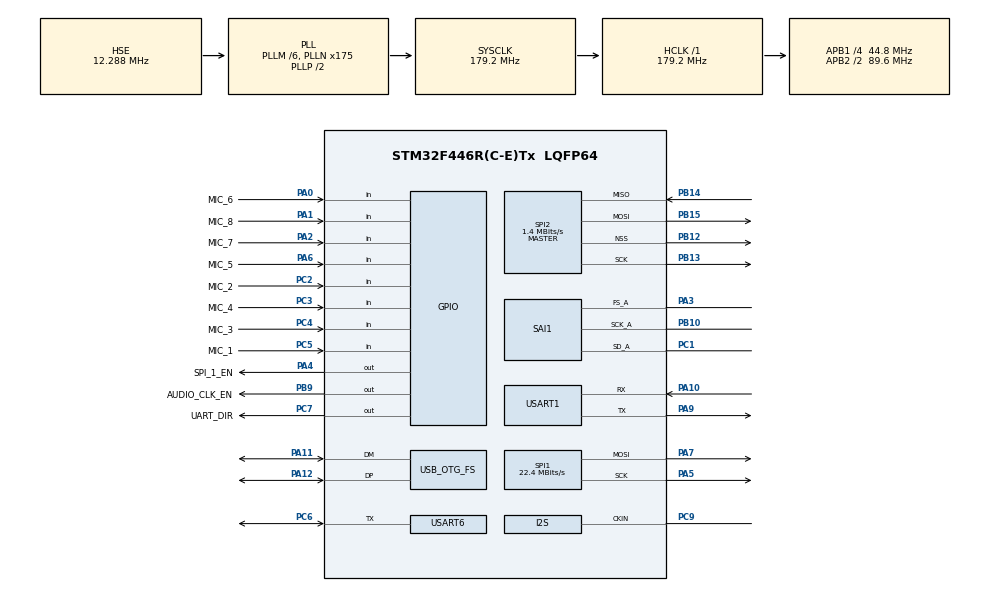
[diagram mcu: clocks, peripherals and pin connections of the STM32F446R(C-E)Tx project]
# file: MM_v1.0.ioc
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Dma.Request0=USART1_RX
Dma.Request1=USART1_TX
Dma.Request2=USART6_RX
Dma.Request3=USART6_TX
Dma.Request4=SPI2_TX
Dma.Request5=SPI1_TX
Dma.Request6=SAI1_A
Dma.SAI1_A.6.Direction=DMA_PERIPH_TO_MEMORY
Dma.SAI1_A.6.FIFOMode=DMA_FIFOMODE_DISABLE
Dma.SAI1_A.6.Instance=DMA2_Stream1
Dma.SAI1_A.6.MemDataAlignment=DMA_MDATAALIGN_WORD
Dma.SAI1_A.6.MemInc=DMA_MINC_ENABLE
Dma.SAI1_A.6.Mode=DMA_CIRCULAR
Dma.SAI1_A.6.PeriphDataAlignment=DMA_PDATAALIGN_WORD
Dma.SAI1_A.6.PeriphInc=DMA_PINC_DISABLE
Dma.SAI1_A.6.Priority=DMA_PRIORITY_HIGH
Dma.SPI1_TX.5.Direction=DMA_MEMORY_TO_PERIPH
Dma.SPI1_TX.5.FIFOMode=DMA_FIFOMODE_DISABLE
Dma.SPI1_TX.5.Instance=DMA2_Stream3
Dma.SPI1_TX.5.MemDataAlignment=DMA_MDATAALIGN_HALFWORD
Dma.SPI1_TX.5.MemInc=DMA_MINC_ENABLE
Dma.SPI1_TX.5.Mode=DMA_NORMAL
Dma.SPI1_TX.5.PeriphDataAlignment=DMA_PDATAALIGN_HALFWORD
Dma.SPI1_TX.5.PeriphInc=DMA_PINC_DISABLE
Dma.SPI1_TX.5.Priority=DMA_PRIORITY_VERY_HIGH
Dma.SPI2_TX.4.Direction=DMA_MEMORY_TO_PERIPH
Dma.SPI2_TX.4.FIFOMode=DMA_FIFOMODE_DISABLE
Dma.SPI2_TX.4.Instance=DMA1_Stream4
Dma.SPI2_TX.4.MemDataAlignment=DMA_MDATAALIGN_HALFWORD
Dma.SPI2_TX.4.MemInc=DMA_MINC_ENABLE
Dma.SPI2_TX.4.Mode=DMA_NORMAL
Dma.SPI2_TX.4.PeriphDataAlignment=DMA_PDATAALIGN_HALFWORD
Dma.SPI2_TX.4.PeriphInc=DMA_PINC_DISABLE
Dma.SPI2_TX.4.Priority=DMA_PRIORITY_LOW
Dma.USART1_RX.0.Direction=DMA_PERIPH_TO_MEMORY
Dma.USART1_RX.0.FIFOMode=DMA_FIFOMODE_DISABLE
Dma.USART1_RX.0.Instance=DMA2_Stream5
Dma.USART1_RX.0.MemDataAlignment=DMA_MDATAALIGN_BYTE
Dma.USART1_RX.0.MemInc=DMA_MINC_ENABLE
Dma.USART1_RX.0.Mode=DMA_NORMAL
Dma.USART1_RX.0.PeriphDataAlignment=DMA_PDATAALIGN_BYTE
Dma.USART1_RX.0.PeriphInc=DMA_PINC_DISABLE
Dma.USART1_RX.0.Priority=DMA_PRIORITY_LOW
Dma.USART1_TX.1.Direction=DMA_MEMORY_TO_PERIPH
Dma.USART1_TX.1.FIFOMode=DMA_FIFOMODE_DISABLE
Dma.USART1_TX.1.Instance=DMA2_Stream7
Dma.USART1_TX.1.MemDataAlignment=DMA_MDATAALIGN_BYTE
Dma.USART1_TX.1.MemInc=DMA_MINC_ENABLE
Dma.USART1_TX.1.Mode=DMA_NORMAL
Dma.USART1_TX.1.PeriphDataAlignment=DMA_PDATAALIGN_BYTE
Dma.USART1_TX.1.PeriphInc=DMA_PINC_DISABLE
Dma.USART1_TX.1.Priority=DMA_PRIORITY_LOW
Dma.USART6_RX.2.Direction=DMA_PERIPH_TO_MEMORY
Dma.USART6_RX.2.FIFOMode=DMA_FIFOMODE_DISABLE
Dma.USART6_RX.2.Instance=DMA2_Stream2
Dma.USART6_RX.2.MemDataAlignment=DMA_MDATAALIGN_BYTE
Dma.USART6_RX.2.MemInc=DMA_MINC_ENABLE
Dma.USART6_RX.2.Mode=DMA_NORMAL
Dma.USART6_RX.2.PeriphDataAlignment=DMA_PDATAALIGN_BYTE
Dma.USART6_RX.2.PeriphInc=DMA_PINC_DISABLE
Dma.USART6_RX.2.Priority=DMA_PRIORITY_LOW
Dma.USART6_TX.3.Direction=DMA_MEMORY_TO_PERIPH
Dma.USART6_TX.3.FIFOMode=DMA_FIFOMODE_DISABLE
Dma.USART6_TX.3.Instance=DMA2_Stream6
Dma.USART6_TX.3.MemDataAlignment=DMA_MDATAALIGN_BYTE
Dma.USART6_TX.3.MemInc=DMA_MINC_ENABLE
Dma.USART6_TX.3.Mode=DMA_NORMAL
Dma.USART6_TX.3.PeriphDataAlignment=DMA_PDATAALIGN_BYTE
Dma.USART6_TX.3.PeriphInc=DMA_PINC_DISABLE
Dma.USART6_TX.3.Priority=DMA_PRIORITY_LOW
Mcu.Family=STM32F4
Mcu.Name=STM32F446R(C-E)Tx
Mcu.Package=LQFP64
NVIC.DMA1_Stream4_IRQn=true\:0\:0\:false\:false\:true\:false
NVIC.DMA2_Stream1_IRQn=true\:0\:0\:false\:false\:true\:false
NVIC.DMA2_Stream2_IRQn=true\:0\:0\:false\:false\:true\:false
NVIC.DMA2_Stream3_IRQn=true\:0\:0\:false\:false\:true\:false
NVIC.DMA2_Stream5_IRQn=true\:0\:0\:false\:false\:true\:false
NVIC.DMA2_Stream6_IRQn=true\:0\:0\:false\:false\:true\:false
NVIC.DMA2_Stream7_IRQn=true\:0\:0\:false\:false\:true\:false
NVIC.OTG_FS_IRQn=true\:0\:0\:false\:false\:true\:false
NVIC.PriorityGroup=NVIC_PRIORITYGROUP_4
NVIC.SPI1_IRQn=true\:0\:0\:false\:false\:true\:true
NVIC.SPI2_IRQn=true\:0\:0\:false\:false\:true\:true
PA0-WKUP.GPIO_Label=MIC_6
PA0-WKUP.Signal=GPIO_Input
PA1.GPIO_Label=MIC_8
PA1.Signal=GPIO_Input
PA10.Mode=Asynchronous
PA10.Signal=USART1_RX
PA11.Mode=Device_Only
PA11.Signal=USB_OTG_FS_DM
PA12.Mode=Device_Only
PA12.Signal=USB_OTG_FS_DP
PA2.GPIO_Label=MIC_7
PA2.Signal=GPIO_Input
PA3.GPIO_Speed=GPIO_SPEED_FREQ_VERY_HIGH
PA3.Mode=SAI_A_Master
PA3.Signal=SAI1_FS_A
PA4.GPIO_Label=SPI_1_EN
PA4.GPIO_Speed=GPIO_SPEED_FREQ_VERY_HIGH
PA4.Signal=GPIO_Output
PA5.Mode=TX_Only_Simplex_Unidirect_Master
PA5.Signal=SPI1_SCK
PA6.GPIO_Label=MIC_5
PA6.Signal=GPIO_Input
PA7.Mode=TX_Only_Simplex_Unidirect_Master
PA7.Signal=SPI1_MOSI
PA9.Mode=Asynchronous
PA9.Signal=USART1_TX
PB10.GPIO_Speed=GPIO_SPEED_FREQ_VERY_HIGH
PB10.Mode=SAI_A_Master
PB10.Signal=SAI1_SCK_A
PB12.Mode=NSS_Signal_Hard_Output
PB12.Signal=SPI2_NSS
PB13.Mode=Full_Duplex_Master
PB13.Signal=SPI2_SCK
PB14.Mode=Full_Duplex_Master
PB14.Signal=SPI2_MISO
PB15.Mode=Full_Duplex_Master
PB15.Signal=SPI2_MOSI
PB9.GPIO_Label=AUDIO_CLK_EN
PB9.GPIO_Speed=GPIO_SPEED_FREQ_VERY_HIGH
PB9.Signal=GPIO_Output
PC1.GPIO_Speed=GPIO_SPEED_FREQ_VERY_HIGH
PC1.Mode=SAI_A_Master
PC1.Signal=SAI1_SD_A
PC14-OSC32_IN.Mode=LSE-External-Oscillator
PC14-OSC32_IN.Signal=RCC_OSC32_IN
PC15-OSC32_OUT.Mode=LSE-External-Oscillator
PC15-OSC32_OUT.Signal=RCC_OSC32_OUT
PC2.GPIO_Label=MIC_2
PC2.Signal=GPIO_Input
PC3.GPIO_Label=MIC_4
PC3.Signal=GPIO_Input
PC4.GPIO_Label=MIC_3
PC4.Signal=GPIO_Input
PC5.GPIO_Label=MIC_1
PC5.Signal=GPIO_Input
PC6.Mode=Half_duplex(single_wire_mode)
PC6.Signal=USART6_TX
PC7.GPIO_Label=UART_DIR
PC7.GPIO_Speed=GPIO_SPEED_FREQ_VERY_HIGH
PC7.Signal=GPIO_Output
PC9.GPIO_Speed=GPIO_SPEED_FREQ_VERY_HIGH
PC9.Mode=Audio_ClockIn
PC9.Signal=I2S_CKIN
PH0-OSC_IN.Mode=HSE-External-Oscillator
PH0-OSC_IN.Signal=RCC_OSC_IN
PH1-OSC_OUT.Mode=HSE-External-Oscillator
PH1-OSC_OUT.Signal=RCC_OSC_OUT
ProjectManager.HeapSize=0x2000
ProjectManager.StackSize=0x4000
ProjectManager.TargetToolchain=MDK-ARM V5
RCC.AHBFreq_Value=179200000
RCC.APB1CLKDivider=RCC_HCLK_DIV4
RCC.APB1Freq_Value=44800000
RCC.APB1TimFreq_Value=89600000
RCC.APB2CLKDivider=RCC_HCLK_DIV2
RCC.APB2Freq_Value=89600000
RCC.APB2TimFreq_Value=179200000
RCC.CortexFreq_Value=179200000
RCC.EXTERNAL_CLOCK_VALUE=12288000
RCC.HCLKFreq_Value=179200000
RCC.HSE_VALUE=12288000
RCC.PLLM=6
RCC.PLLN=175
RCC.PLLSAIM=8
RCC.PLLSAIN=125
RCC.PLLSAIP=RCC_PLLSAIP_DIV4
RCC.PLLSAIQ=4
RCC.PLLSAIQDiv=4
RCC.PLLSourceVirtual=RCC_PLLSOURCE_HSE
RCC.SAIACLockSelection=RCC_SAI1CLKSOURCE_EXT
RCC.SYSCLKFreq_VALUE=179200000
RCC.SYSCLKSource=RCC_SYSCLKSOURCE_PLLCLK
RCC.USBCLockSelection=RCC_CLK48CLKSOURCE_PLLSAIP
RCC.USBFreq_Value=48000000
RCC.VCOOutputFreq_Value=358400000
SAI1.ActiveFrameLength-SAI_A_Master=1
SAI1.AudioFrequency-SAI_A_Master=SAI_AUDIO_FREQUENCY_22K
SAI1.AudioMode-SAI_A_Master=SAI_MODEMASTER_RX
SAI1.DataSize-SAI_A_Master=SAI_DATASIZE_20
SAI1.ErrorAudioFreq-SAI_A_Master=50.0 %
SAI1.FSOffset-SAI_A_Master=SAI_FS_FIRSTBIT
SAI1.FSPolarity-SAI_A_Master=SAI_FS_ACTIVE_HIGH
SAI1.FirstBitOffset-SAI_A_Master=0
SAI1.FrameLength-SAI_A_Master=256
SAI1.Instance-SAI_A_Master=SAI$Index_Block_A
SAI1.MClockEnable-SAI_A_Master=SAI_MASTERCLOCK_DISABLE
SAI1.NoDivider-SAI_A_Master=SAI_MASTERDIVIDER_ENABLE
SAI1.OutputDrive-SAI_A_Master=SAI_OUTPUTDRIVE_DISABLE
SAI1.RealAudioFreq-SAI_A_Master=24.0 KHz
SAI1.SlotActive-SAI_A_Master=0x0000FFFF
SAI1.SlotNumber-SAI_A_Master=8
SAI1.SlotSize-SAI_A_Master=SAI_SLOTSIZE_32B
SAI1.Synchro-SAI_A_Master=SAI_ASYNCHRONOUS
SAI1.VirtualMode-SAI_A_Master=VM_MASTER
SAI1.VirtualSlotActive-SAI_A_Master=SAI_SLOTACTIVE_ALL
SPI1.BaudRatePrescaler=SPI_BAUDRATEPRESCALER_4
SPI1.CLKPhase=SPI_PHASE_2EDGE
SPI1.CLKPolarity=SPI_POLARITY_HIGH
SPI1.CRCCalculation=SPI_CRCCALCULATION_DISABLE
SPI1.CalculateBaudRate=22.4 MBits/s
SPI1.DataSize=SPI_DATASIZE_16BIT
SPI1.Direction=SPI_DIRECTION_2LINES
SPI1.Mode=SPI_MODE_MASTER
SPI1.VirtualType=VM_MASTER
SPI2.BaudRatePrescaler=SPI_BAUDRATEPRESCALER_32
SPI2.CLKPhase=SPI_PHASE_2EDGE
SPI2.CLKPolarity=SPI_POLARITY_HIGH
SPI2.CRCCalculation=SPI_CRCCALCULATION_DISABLE
SPI2.CalculateBaudRate=1.4 MBits/s
SPI2.DataSize=SPI_DATASIZE_16BIT
SPI2.Direction=SPI_DIRECTION_2LINES
SPI2.Mode=SPI_MODE_MASTER
SPI2.VirtualNSS=VM_NSSHARD
SPI2.VirtualType=VM_MASTER
USART1.VirtualMode=VM_ASYNC
USART6.VirtualMode=VM_ASYNC
USB_DEVICE.CLASS_NAME_FS=AUDIO
USB_DEVICE.USBD_AUDIO_FREQ-AUDIO_FS=24000
USB_DEVICE.USBD_LPM_ENABLED-AUDIO_FS=0
USB_DEVICE.VirtualMode-AUDIO_FS=Audio
USB_DEVICE.VirtualModeFS=Audio_FS
USB_OTG_FS.VirtualMode=Device_Only
VP_USB_DEVICE_VS_USB_DEVICE_AUDIO_FS.Mode=AUDIO_FS
board=MM

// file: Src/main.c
/**
  ******************************************************************************
  * @file           : main.c
  * @brief          : Main program body
  ******************************************************************************
  * This notice applies to any and all portions of this file
  * that are not between comment pairs USER CODE BEGIN and
  * USER CODE END. Other portions of this file, whether
  * inserted by the user or by software development tools
  * are owned by their respective copyright owners.
  *
  * Copyright (c) 2018 STMicroelectronics International N.V.
  * All rights reserved.
  *
  * Redistribution and use in source and binary forms, with or without
  * modification, are permitted, provided that the following conditions are met:
  *
  * 1. Redistribution of source code must retain the above copyright notice,
  *    this list of conditions and the following disclaimer.
  * 2. Redistributions in binary form must reproduce the above copyright notice,
  *    this list of conditions and the following disclaimer in the documentation
  *    and/or other materials provided with the distribution.
  * 3. Neither the name of STMicroelectronics nor the names of other
  *    contributors to this software may be used to endorse or promote products
  *    derived from this software without specific written permission.
  * 4. This software, including modifications and/or derivative works of this
  *    software, must execute solely and exclusively on microcontroller or
  *    microprocessor devices manufactured by or for STMicroelectronics.
  * 5. Redistribution and use of this software other than as permitted under
  *    this license is void and will automatically terminate your rights under
  *    this license.
  *
  * THIS SOFTWARE IS PROVIDED BY STMICROELECTRONICS AND CONTRIBUTORS "AS IS"
  * AND ANY EXPRESS, IMPLIED OR STATUTORY WARRANTIES, INCLUDING, BUT NOT
  * LIMITED TO, THE IMPLIED WARRANTIES OF MERCHANTABILITY, FITNESS FOR A
  * PARTICULAR PURPOSE AND NON-INFRINGEMENT OF THIRD PARTY INTELLECTUAL PROPERTY
  * RIGHTS ARE DISCLAIMED TO THE FULLEST EXTENT PERMITTED BY LAW. IN NO EVENT
  * SHALL STMICROELECTRONICS OR CONTRIBUTORS BE LIABLE FOR ANY DIRECT, INDIRECT,
  * INCIDENTAL, SPECIAL, EXEMPLARY, OR CONSEQUENTIAL DAMAGES (INCLUDING, BUT NOT
  * LIMITED TO, PROCUREMENT OF SUBSTITUTE GOODS OR SERVICES; LOSS OF USE, DATA,
  * OR PROFITS; OR BUSINESS INTERRUPTION) HOWEVER CAUSED AND ON ANY THEORY OF
  * LIABILITY, WHETHER IN CONTRACT, STRICT LIABILITY, OR TORT (INCLUDING
  * NEGLIGENCE OR OTHERWISE) ARISING IN ANY WAY OUT OF THE USE OF THIS SOFTWARE,
  * EVEN IF ADVISED OF THE POSSIBILITY OF SUCH DAMAGE.
  *
  ******************************************************************************
  */
#include "main.h"
#include "stm32f4xx_hal.h"
#include "usb_device.h"

/* USER CODE BEGIN Includes */

#include "MM_app_sampling.h"
#include "MM_app_transmit.h"
#include "MM_app_control.h"

/* USER CODE END Includes */

SAI_HandleTypeDef hsai_BlockA1;
DMA_HandleTypeDef hdma_sai1_a;

SPI_HandleTypeDef hspi1;
SPI_HandleTypeDef hspi2;
DMA_HandleTypeDef hdma_spi1_tx;
DMA_HandleTypeDef hdma_spi2_tx;

UART_HandleTypeDef huart1;
UART_HandleTypeDef huart6;
DMA_HandleTypeDef hdma_usart1_rx;
DMA_HandleTypeDef hdma_usart1_tx;
DMA_HandleTypeDef hdma_usart6_rx;
DMA_HandleTypeDef hdma_usart6_tx;

/* USER CODE BEGIN PV */
/* Private variables ---------------------------------------------------------*/

int32_t tempBuffer[960];

/* USER CODE END PV */

void SystemClock_Config(void);
static void MX_GPIO_Init(void);
static void MX_DMA_Init(void);
static void MX_SPI1_Init(void);
static void MX_SPI2_Init(void);
static void MX_USART1_UART_Init(void);
static void MX_USART6_UART_Init(void);
static void MX_SAI1_Init(void);

/* USER CODE BEGIN PFP */
/* Private function prototypes -----------------------------------------------*/

/* USER CODE END PFP */

int main(void)
{

  /* MCU Configuration----------------------------------------------------------*/

  /* Reset of all peripherals, Initializes the Flash interface and the Systick. */
  HAL_Init();

  /* Configure the system clock */
  SystemClock_Config();

  /* Initialize all configured peripherals */
  MX_GPIO_Init();
  MX_DMA_Init();
  MX_SPI1_Init();
  MX_SPI2_Init();
  MX_USART1_UART_Init();
  MX_USART6_UART_Init();
  MX_SAI1_Init();
  MX_USB_DEVICE_Init();
  /* USER CODE BEGIN 2 */

  uint8_t msg[] = "app_start\n\r";
  HAL_UART_Transmit(&huart1, (uint8_t*)msg, sizeof(msg), 0xFFFF);

  app_control_init();

  /* USER CODE END 2 */

  /* Infinite loop */
  /* USER CODE BEGIN WHILE */

  HAL_SAI_Receive_DMA(&hsai_BlockA1, (uint8_t*)tempBuffer, 960);

  while (1)
  {
  /* USER CODE END WHILE */

  }

}

void SystemClock_Config(void)
{

  RCC_OscInitTypeDef RCC_OscInitStruct;
  RCC_ClkInitTypeDef RCC_ClkInitStruct;
  RCC_PeriphCLKInitTypeDef PeriphClkInitStruct;

    /**Configure the main internal regulator output voltage
    */
  __HAL_RCC_PWR_CLK_ENABLE();

  __HAL_PWR_VOLTAGESCALING_CONFIG(PWR_REGULATOR_VOLTAGE_SCALE1);

    /**Initializes the CPU, AHB and APB busses clocks
    */
  RCC_OscInitStruct.OscillatorType = RCC_OSCILLATORTYPE_HSE;
  RCC_OscInitStruct.HSEState = RCC_HSE_ON;
  RCC_OscInitStruct.PLL.PLLState = RCC_PLL_ON;
  RCC_OscInitStruct.PLL.PLLSource = RCC_PLLSOURCE_HSE;
  RCC_OscInitStruct.PLL.PLLM = 6;
  RCC_OscInitStruct.PLL.PLLN = 175;
  RCC_OscInitStruct.PLL.PLLP = RCC_PLLP_DIV2;
  RCC_OscInitStruct.PLL.PLLQ = 2;
  RCC_OscInitStruct.PLL.PLLR = 2;
  if (HAL_RCC_OscConfig(&RCC_OscInitStruct) != HAL_OK)
  {
    _Error_Handler(__FILE__, __LINE__);
  }

    /**Activate the Over-Drive mode
    */
  if (HAL_PWREx_EnableOverDrive() != HAL_OK)
  {
    _Error_Handler(__FILE__, __LINE__);
  }

    /**Initializes the CPU, AHB and APB busses clocks
    */
  RCC_ClkInitStruct.ClockType = RCC_CLOCKTYPE_HCLK|RCC_CLOCKTYPE_SYSCLK
                              |RCC_CLOCKTYPE_PCLK1|RCC_CLOCKTYPE_PCLK2;
  RCC_ClkInitStruct.SYSCLKSource = RCC_SYSCLKSOURCE_PLLCLK;
  RCC_ClkInitStruct.AHBCLKDivider = RCC_SYSCLK_DIV1;
  RCC_ClkInitStruct.APB1CLKDivider = RCC_HCLK_DIV4;
  RCC_ClkInitStruct.APB2CLKDivider = RCC_HCLK_DIV2;

  if (HAL_RCC_ClockConfig(&RCC_ClkInitStruct, FLASH_LATENCY_5) != HAL_OK)
  {
    _Error_Handler(__FILE__, __LINE__);
  }

  PeriphClkInitStruct.PeriphClockSelection = RCC_PERIPHCLK_SAI1|RCC_PERIPHCLK_CLK48;
  PeriphClkInitStruct.PLLSAI.PLLSAIM = 8;
  PeriphClkInitStruct.PLLSAI.PLLSAIN = 125;
  PeriphClkInitStruct.PLLSAI.PLLSAIQ = 4;
  PeriphClkInitStruct.PLLSAI.PLLSAIP = RCC_PLLSAIP_DIV4;
  PeriphClkInitStruct.PLLSAIDivQ = 4;
  PeriphClkInitStruct.Clk48ClockSelection = RCC_CLK48CLKSOURCE_PLLSAIP;
  PeriphClkInitStruct.Sai1ClockSelection = RCC_SAI1CLKSOURCE_EXT;
  if (HAL_RCCEx_PeriphCLKConfig(&PeriphClkInitStruct) != HAL_OK)
  {
    _Error_Handler(__FILE__, __LINE__);
  }

    /**Configure the Systick interrupt time
    */
  HAL_SYSTICK_Config(HAL_RCC_GetHCLKFreq()/1000);

    /**Configure the Systick
    */
  HAL_SYSTICK_CLKSourceConfig(SYSTICK_CLKSOURCE_HCLK);

  /* SysTick_IRQn interrupt configuration */
  HAL_NVIC_SetPriority(SysTick_IRQn, 0, 0);
}

/* SAI1 init function */
static void MX_SAI1_Init(void)
{

  hsai_BlockA1.Instance = SAI1_Block_A;
  hsai_BlockA1.Init.Protocol = SAI_FREE_PROTOCOL;
  hsai_BlockA1.Init.AudioMode = SAI_MODEMASTER_RX;
  hsai_BlockA1.Init.DataSize = SAI_DATASIZE_20;
  hsai_BlockA1.Init.FirstBit = SAI_FIRSTBIT_MSB;
  hsai_BlockA1.Init.ClockStrobing = SAI_CLOCKSTROBING_FALLINGEDGE;
  hsai_BlockA1.Init.Synchro = SAI_ASYNCHRONOUS;
  hsai_BlockA1.Init.OutputDrive = SAI_OUTPUTDRIVE_DISABLE;
  hsai_BlockA1.Init.NoDivider = SAI_MASTERDIVIDER_ENABLE;
  hsai_BlockA1.Init.FIFOThreshold = SAI_FIFOTHRESHOLD_EMPTY;
  hsai_BlockA1.Init.ClockSource = SAI_CLKSOURCE_NA;
  hsai_BlockA1.Init.AudioFrequency = SAI_AUDIO_FREQUENCY_22K;
  hsai_BlockA1.Init.SynchroExt = SAI_SYNCEXT_DISABLE;
  hsai_BlockA1.Init.MonoStereoMode = SAI_STEREOMODE;
  hsai_BlockA1.Init.CompandingMode = SAI_NOCOMPANDING;
  hsai_BlockA1.FrameInit.FrameLength = 256;
  hsai_BlockA1.FrameInit.ActiveFrameLength = 1;
  hsai_BlockA1.FrameInit.FSDefinition = SAI_FS_STARTFRAME;
  hsai_BlockA1.FrameInit.FSPolarity = SAI_FS_ACTIVE_HIGH;
  hsai_BlockA1.FrameInit.FSOffset = SAI_FS_FIRSTBIT;
  hsai_BlockA1.SlotInit.FirstBitOffset = 0;
  hsai_BlockA1.SlotInit.SlotSize = SAI_SLOTSIZE_32B;
  hsai_BlockA1.SlotInit.SlotNumber = 8;
  hsai_BlockA1.SlotInit.SlotActive = 0x0000FFFF;
  if (HAL_SAI_Init(&hsai_BlockA1) != HAL_OK)
  {
    _Error_Handler(__FILE__, __LINE__);
  }

}

/* SPI1 init function */
static void MX_SPI1_Init(void)
{

  /* SPI1 parameter configuration*/
  hspi1.Instance = SPI1;
  hspi1.Init.Mode = SPI_MODE_MASTER;
  hspi1.Init.Direction = SPI_DIRECTION_2LINES;
  hspi1.Init.DataSize = SPI_DATASIZE_16BIT;
  hspi1.Init.CLKPolarity = SPI_POLARITY_HIGH;
  hspi1.Init.CLKPhase = SPI_PHASE_2EDGE;
  hspi1.Init.NSS = SPI_NSS_SOFT;
  hspi1.Init.BaudRatePrescaler = SPI_BAUDRATEPRESCALER_4;
  hspi1.Init.FirstBit = SPI_FIRSTBIT_MSB;
  hspi1.Init.TIMode = SPI_TIMODE_DISABLE;
  hspi1.Init.CRCCalculation = SPI_CRCCALCULATION_DISABLE;
  hspi1.Init.CRCPolynomial = 10;
  if (HAL_SPI_Init(&hspi1) != HAL_OK)
  {
    _Error_Handler(__FILE__, __LINE__);
  }

}

/* SPI2 init function */
static void MX_SPI2_Init(void)
{

  /* SPI2 parameter configuration*/
  hspi2.Instance = SPI2;
  hspi2.Init.Mode = SPI_MODE_MASTER;
  hspi2.Init.Direction = SPI_DIRECTION_2LINES;
  hspi2.Init.DataSize = SPI_DATASIZE_16BIT;
  hspi2.Init.CLKPolarity = SPI_POLARITY_HIGH;
  hspi2.Init.CLKPhase = SPI_PHASE_2EDGE;
  hspi2.Init.NSS = SPI_NSS_HARD_OUTPUT;
  hspi2.Init.BaudRatePrescaler = SPI_BAUDRATEPRESCALER_32;
  hspi2.Init.FirstBit = SPI_FIRSTBIT_MSB;
  hspi2.Init.TIMode = SPI_TIMODE_DISABLE;
  hspi2.Init.CRCCalculation = SPI_CRCCALCULATION_DISABLE;
  hspi2.Init.CRCPolynomial = 10;
  if (HAL_SPI_Init(&hspi2) != HAL_OK)
  {
    _Error_Handler(__FILE__, __LINE__);
  }

}

/* USART1 init function */
static void MX_USART1_UART_Init(void)
{

  huart1.Instance = USART1;
  huart1.Init.BaudRate = 115200;
  huart1.Init.WordLength = UART_WORDLENGTH_8B;
  huart1.Init.StopBits = UART_STOPBITS_1;
  huart1.Init.Parity = UART_PARITY_NONE;
  huart1.Init.Mode = UART_MODE_TX_RX;
  huart1.Init.HwFlowCtl = UART_HWCONTROL_NONE;
  huart1.Init.OverSampling = UART_OVERSAMPLING_16;
  if (HAL_UART_Init(&huart1) != HAL_OK)
  {
    _Error_Handler(__FILE__, __LINE__);
  }

}

/* USART6 init function */
static void MX_USART6_UART_Init(void)
{

  huart6.Instance = USART6;
  huart6.Init.BaudRate = 115200;
  huart6.Init.WordLength = UART_WORDLENGTH_8B;
  huart6.Init.StopBits = UART_STOPBITS_1;
  huart6.Init.Parity = UART_PARITY_NONE;
  huart6.Init.Mode = UART_MODE_TX_RX;
  huart6.Init.HwFlowCtl = UART_HWCONTROL_NONE;
  huart6.Init.OverSampling = UART_OVERSAMPLING_16;
  if (HAL_HalfDuplex_Init(&huart6) != HAL_OK)
  {
    _Error_Handler(__FILE__, __LINE__);
  }

}

static void MX_DMA_Init(void)
{
  /* DMA controller clock enable */
  __HAL_RCC_DMA2_CLK_ENABLE();
  __HAL_RCC_DMA1_CLK_ENABLE();

  /* DMA interrupt init */
  /* DMA1_Stream4_IRQn interrupt configuration */
  HAL_NVIC_SetPriority(DMA1_Stream4_IRQn, 0, 0);
  HAL_NVIC_EnableIRQ(DMA1_Stream4_IRQn);
  /* DMA2_Stream1_IRQn interrupt configuration */
  HAL_NVIC_SetPriority(DMA2_Stream1_IRQn, 0, 0);
  HAL_NVIC_EnableIRQ(DMA2_Stream1_IRQn);
  /* DMA2_Stream2_IRQn interrupt configuration */
  HAL_NVIC_SetPriority(DMA2_Stream2_IRQn, 0, 0);
  HAL_NVIC_EnableIRQ(DMA2_Stream2_IRQn);
  /* DMA2_Stream3_IRQn interrupt configuration */
  HAL_NVIC_SetPriority(DMA2_Stream3_IRQn, 0, 0);
  HAL_NVIC_EnableIRQ(DMA2_Stream3_IRQn);
  /* DMA2_Stream5_IRQn interrupt configuration */
  HAL_NVIC_SetPriority(DMA2_Stream5_IRQn, 0, 0);
  HAL_NVIC_EnableIRQ(DMA2_Stream5_IRQn);
  /* DMA2_Stream6_IRQn interrupt configuration */
  HAL_NVIC_SetPriority(DMA2_Stream6_IRQn, 0, 0);
  HAL_NVIC_EnableIRQ(DMA2_Stream6_IRQn);
  /* DMA2_Stream7_IRQn interrupt configuration */
  HAL_NVIC_SetPriority(DMA2_Stream7_IRQn, 0, 0);
  HAL_NVIC_EnableIRQ(DMA2_Stream7_IRQn);

}

/** Configure pins as
        * Analog
        * Input
        * Output
        * EVENT_OUT
        * EXTI
     PC9   ------> I2S_CKIN
*/
static void MX_GPIO_Init(void)
{

  GPIO_InitTypeDef GPIO_InitStruct;

  /* GPIO Ports Clock Enable */
  __HAL_RCC_GPIOC_CLK_ENABLE();
  __HAL_RCC_GPIOH_CLK_ENABLE();
  __HAL_RCC_GPIOA_CLK_ENABLE();
  __HAL_RCC_GPIOB_CLK_ENABLE();

  /*Configure GPIO pin Output Level */
  HAL_GPIO_WritePin(SPI_1_EN_GPIO_Port, SPI_1_EN_Pin, GPIO_PIN_RESET);

  /*Configure GPIO pin Output Level */
  HAL_GPIO_WritePin(UART_DIR_GPIO_Port, UART_DIR_Pin, GPIO_PIN_RESET);

  /*Configure GPIO pin Output Level */
  HAL_GPIO_WritePin(AUDIO_CLK_EN_GPIO_Port, AUDIO_CLK_EN_Pin, GPIO_PIN_RESET);

  /*Configure GPIO pins : MIC_2_Pin MIC_4_Pin MIC_3_Pin MIC_1_Pin */
  GPIO_InitStruct.Pin = MIC_2_Pin|MIC_4_Pin|MIC_3_Pin|MIC_1_Pin;
  GPIO_InitStruct.Mode = GPIO_MODE_INPUT;
  GPIO_InitStruct.Pull = GPIO_NOPULL;
  HAL_GPIO_Init(GPIOC, &GPIO_InitStruct);

  /*Configure GPIO pins : MIC_6_Pin MIC_8_Pin MIC_7_Pin MIC_5_Pin */
  GPIO_InitStruct.Pin = MIC_6_Pin|MIC_8_Pin|MIC_7_Pin|MIC_5_Pin;
  GPIO_InitStruct.Mode = GPIO_MODE_INPUT;
  GPIO_InitStruct.Pull = GPIO_NOPULL;
  HAL_GPIO_Init(GPIOA, &GPIO_InitStruct);

  /*Configure GPIO pin : SPI_1_EN_Pin */
  GPIO_InitStruct.Pin = SPI_1_EN_Pin;
  GPIO_InitStruct.Mode = GPIO_MODE_OUTPUT_PP;
  GPIO_InitStruct.Pull = GPIO_NOPULL;
  GPIO_InitStruct.Speed = GPIO_SPEED_FREQ_VERY_HIGH;
  HAL_GPIO_Init(SPI_1_EN_GPIO_Port, &GPIO_InitStruct);

  /*Configure GPIO pin : UART_DIR_Pin */
  GPIO_InitStruct.Pin = UART_DIR_Pin;
  GPIO_InitStruct.Mode = GPIO_MODE_OUTPUT_PP;
  GPIO_InitStruct.Pull = GPIO_NOPULL;
  GPIO_InitStruct.Speed = GPIO_SPEED_FREQ_VERY_HIGH;
  HAL_GPIO_Init(UART_DIR_GPIO_Port, &GPIO_InitStruct);

  /*Configure GPIO pin : PC9 */
  GPIO_InitStruct.Pin = GPIO_PIN_9;
  GPIO_InitStruct.Mode = GPIO_MODE_AF_PP;
  GPIO_InitStruct.Pull = GPIO_NOPULL;
  GPIO_InitStruct.Speed = GPIO_SPEED_FREQ_VERY_HIGH;
  GPIO_InitStruct.Alternate = GPIO_AF5_SPI1;
  HAL_GPIO_Init(GPIOC, &GPIO_InitStruct);

  /*Configure GPIO pin : AUDIO_CLK_EN_Pin */
  GPIO_InitStruct.Pin = AUDIO_CLK_EN_Pin;
  GPIO_InitStruct.Mode = GPIO_MODE_OUTPUT_PP;
  GPIO_InitStruct.Pull = GPIO_NOPULL;
  GPIO_InitStruct.Speed = GPIO_SPEED_FREQ_VERY_HIGH;
  HAL_GPIO_Init(AUDIO_CLK_EN_GPIO_Port, &GPIO_InitStruct);

}

void _Error_Handler(char *file, int line)
{
  while(1)
  {
  }
}

/************************ (C) COPYRIGHT STMicroelectronics *****END OF FILE****/
